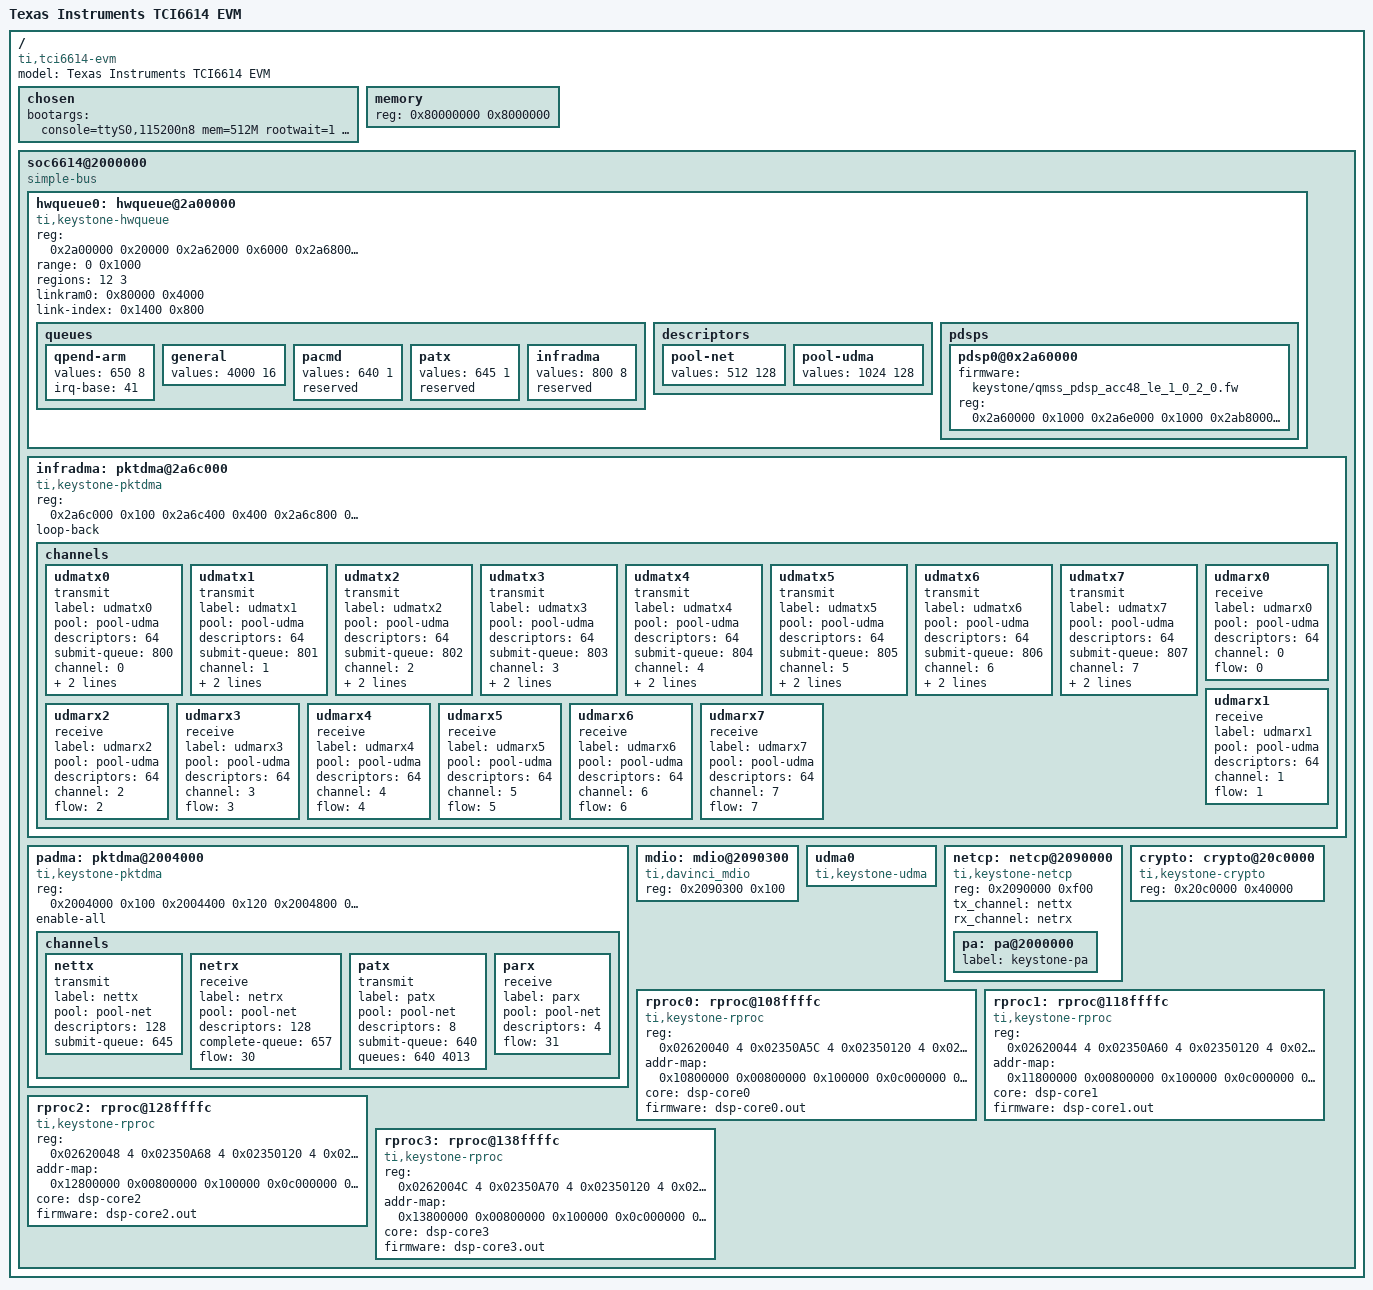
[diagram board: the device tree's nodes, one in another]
/dts-v1/;
/include/ "skeleton.dtsi"

/ {
	model = "Texas Instruments TCI6614 EVM";
	compatible = "ti,tci6614-evm";
	#address-cells = <1>;
	#size-cells = <1>;

	chosen {
		bootargs = "console=ttyS0,115200n8 mem=512M rootwait=1 rw ubi.mtd=2,2048 rootfstype=ubifs root=ubi0:rootfs";
	};

	memory {
		device_type = "memory";
		reg = <0x80000000 0x8000000>;
	};

	soc6614@2000000 {
		#address-cells = <1>;
		#size-cells = <1>;
		compatible = "simple-bus", "ti,tci6614-bus";
		ranges;

		hwqueue0: hwqueue@2a00000 {
			compatible = "ti,keystone-hwqueue";
			#address-cells = <1>;
			#size-cells = <1>;
			ranges;
			reg = <0x2a00000 0x20000	/* 0 - peek	*/
			       0x2a62000 0x6000		/* 1 - status	*/
			       0x2a68000 0x2000		/* 2 - config	*/
			       0x2a6a000 0x4000		/* 3 - region	*/
			       0x2a20000 0x20000>;	/* 4 - push/pop	*/
			range		= <0 0x1000>;
			regions		= <12 3>;
			linkram0	= <0x80000 0x4000>;
			link-index	= <0x1400 0x800>;
			queues {
				qpend-arm {
					values = <650 8>;
					irq-base= <41>;
				};
				general {
					values = <4000 16>;
				};
				pacmd {
					values = <640 1>;
					reserved;
				};
				patx {
					values = <645 1>;
					reserved;
				};
				infradma {
					values = <800 8>;
					reserved;
				};
			};
			descriptors {
				pool-net {
					values = <512 128>;	/* num_desc desc_size */
				};
				pool-udma {
					values = <1024 128>;	/* num_desc desc_size */
				};
			};
			pdsps {
				#address-cells = <1>;
				#size-cells = <1>;
				ranges;
				pdsp0@0x2a60000 {
					firmware = "keystone/qmss_pdsp_acc48_le_1_0_2_0.fw";
					reg = <0x2a60000 0x1000    /*iram */
					       0x2a6e000 0x1000    /*reg*/
					       0x2ab8000 0x4000>;  /*cmd*/
				};
			};
		};

		infradma: pktdma@2a6c000 {
			compatible = "ti,keystone-pktdma";
			reg = <0x2a6c000 0x100		/* 0 - global  */
			       0x2a6c400 0x400		/* 1 - txchan  */
			       0x2a6c800 0x400		/* 2 - rxchan  */
			       0x2a6cc00 0x400		/* 3 - txsched */
			       0x2a6d000 0x400>;	/* 4 - rxflow  */
			loop-back;
			/* big-endian; */
			/* enable-all; */
			/* debug; */
			channels {
				udmatx0 {
					transmit;
					label		= "udmatx0";
					pool		= "pool-udma";
					descriptors	= <64>;
					submit-queue	= <800>;
					/* complete-queue = <xx>; */
					/* debug; */
					channel		= <0>;
					priority	= <1>;
					flowtag		= <0>;
				};
				udmatx1 {
					transmit;
					label		= "udmatx1";
					pool		= "pool-udma";
					descriptors	= <64>;
					submit-queue	= <801>;
					/* complete-queue = <xx>; */
					/* debug; */
					channel		= <1>;
					priority	= <1>;
					flowtag		= <1>;
				};
				udmatx2 {
					transmit;
					label		= "udmatx2";
					pool		= "pool-udma";
					descriptors	= <64>;
					submit-queue	= <802>;
					/* complete-queue = <xx>; */
					/* debug; */
					channel		= <2>;
					priority	= <1>;
					flowtag		= <2>;
				};
				udmatx3 {
					transmit;
					label		= "udmatx3";
					pool		= "pool-udma";
					descriptors	= <64>;
					submit-queue	= <803>;
					/* complete-queue = <xx>; */
					/* debug; */
					channel		= <3>;
					priority	= <1>;
					flowtag		= <3>;
				};
				udmatx4 {
					transmit;
					label		= "udmatx4";
					pool		= "pool-udma";
					descriptors	= <64>;
					submit-queue	= <804>;
					/* complete-queue = <xx>; */
					/* debug; */
					channel		= <4>;
					priority	= <1>;
					flowtag		= <4>;
				};
				udmatx5 {
					transmit;
					label		= "udmatx5";
					pool		= "pool-udma";
					descriptors	= <64>;
					submit-queue	= <805>;
					/* complete-queue = <xx>; */
					/* debug; */
					channel		= <5>;
					priority	= <1>;
					flowtag		= <5>;
				};
				udmatx6 {
					transmit;
					label		= "udmatx6";
					pool		= "pool-udma";
					descriptors	= <64>;
					submit-queue	= <806>;
					/* complete-queue = <xx>; */
					/* debug; */
					channel		= <6>;
					priority	= <1>;
					flowtag		= <6>;
				};
				udmatx7 {
					transmit;
					label		= "udmatx7";
					pool		= "pool-udma";
					descriptors	= <64>;
					submit-queue	= <807>;
					/* complete-queue = <xx>; */
					/* debug; */
					channel		= <7>;
					priority	= <1>;
					flowtag		= <7>;
				};
				udmarx0 {
					receive;
					label		= "udmarx0";
					pool		= "pool-udma";
					descriptors	= <64>;
					/* submit-queue   = <xx>; */
					/* complete-queue = <xx>; */
					/* debug; */
					channel		= <0>;
					flow		= <0>;
				};
				udmarx1 {
					receive;
					label		= "udmarx1";
					pool		= "pool-udma";
					descriptors	= <64>;
					/* submit-queue   = <xx>; */
					/* complete-queue = <xx>; */
					/* debug; */
					channel		= <1>;
					flow		= <1>;
				};
				udmarx2 {
					receive;
					label		= "udmarx2";
					pool		= "pool-udma";
					descriptors	= <64>;
					/* submit-queue   = <xx>; */
					/* complete-queue = <xx>; */
					/* debug; */
					channel		= <2>;
					flow		= <2>;
				};
				udmarx3 {
					receive;
					label		= "udmarx3";
					pool		= "pool-udma";
					descriptors	= <64>;
					/* submit-queue   = <xx>; */
					/* complete-queue = <xx>; */
					/* debug; */
					channel		= <3>;
					flow		= <3>;
				};
				udmarx4 {
					receive;
					label		= "udmarx4";
					pool		= "pool-udma";
					descriptors	= <64>;
					/* submit-queue   = <xx>; */
					/* complete-queue = <xx>; */
					/* debug; */
					channel		= <4>;
					flow		= <4>;
				};
				udmarx5 {
					receive;
					label		= "udmarx5";
					pool		= "pool-udma";
					descriptors	= <64>;
					/* submit-queue   = <xx>; */
					/* complete-queue = <xx>; */
					/* debug; */
					channel		= <5>;
					flow		= <5>;
				};
				udmarx6 {
					receive;
					label		= "udmarx6";
					pool		= "pool-udma";
					descriptors	= <64>;
					/* submit-queue   = <xx>; */
					/* complete-queue = <xx>; */
					/* debug; */
					channel		= <6>;
					flow		= <6>;
				};
				udmarx7 {
					receive;
					label		= "udmarx7";
					pool		= "pool-udma";
					descriptors	= <64>;
					/* submit-queue   = <xx>; */
					/* complete-queue = <xx>; */
					/* debug; */
					channel		= <7>;
					flow		= <7>;
				};
			};
		};

		padma: pktdma@2004000 {
			compatible = "ti,keystone-pktdma";
			reg = <0x2004000 0x100		/* 0 - global  */
			       0x2004400 0x120		/* 1 - txchan  */
			       0x2004800 0x300		/* 2 - rxchan  */
			       0x2004c00 0x120		/* 3 - txsched */
			       0x2005000 0x400>;	/* 4 - rxflow  */
			/* loop-back;  */
			/* bigendian; */
			enable-all;
			/* debug; */
			channels {
				nettx {
					transmit;
					label		= "nettx";
					pool		= "pool-net";
					descriptors	= <128>;
					submit-queue	= <645>;
					/* complete-queue = <xx>; */
					/* debug; */
					/* channel = <0>; */
					/* priority = <1>; */
				};
				netrx {
					receive;
					label		= "netrx";
					pool		= "pool-net";
					descriptors	= <128>;
					/* submit-queue   = <xx>; */
					complete-queue = <657>;
					/* debug; */
					/* channel = <0>; */
					flow		= <30>;
				};
				patx {
					transmit;
					label		= "patx";
					pool		= "pool-net";
					descriptors	= <8>;
					submit-queue	= <640>;
					/* complete-queue = <xx>; */
					/* debug; */
					/* channel = <xx>; */
					/* priority = <1>; */
					queues		= <640 4013>;
				};
				parx {
					receive;
					label		= "parx";
					pool		= "pool-net";
					descriptors	= <4>;
					/* submit-queue   = <xx>; */
					/* complete-queue = <xx>; */
					/* debug; */
					/* channel = <0>; */
					flow		= <31>;
				};
			};
		};

		mdio: mdio@2090300 {
			compatible	= "ti,davinci_mdio";
			reg		= <0x2090300 0x100>;
		};

		udma0 {
			compatible = "ti,keystone-udma";
		};

		netcp: netcp@2090000 {
			reg = <0x2090000 0xf00>;
			compatible = "ti,keystone-netcp";

			tx_channel = "nettx";
			rx_channel = "netrx";
			pa: pa@2000000 {
				label = "keystone-pa";
			};

		};

		crypto: crypto@20c0000 {
			compatible = "ti,keystone-crypto";
			reg = <0x20c0000 0x40000>;
		};

		rproc0: rproc@108ffffc {
			compatible = "ti,keystone-rproc";
			reg = <0x02620040 4				/* boot address register */
			       0x02350A5C 4				/* module control register */
			       0x02350120 4				/* power domain transition command register */
			       0x02620240 4>;				/* ipc interrupt generation register */
			addr-map = <0x10800000 0x00800000 0x100000	/* l2-ram  global, local, size */
				    0x0c000000 0x0c000000 0x200000	/* msmc-sram  global, local, size */
				    0xa0000000 0xa0000000 0x20000000>;	/* ddr3-sram  global, local, size */
			core = "dsp-core0";
			firmware = "dsp-core0.out";
		};

		rproc1: rproc@118ffffc {
			compatible = "ti,keystone-rproc";
			reg = <0x02620044 4
			       0x02350A60 4
			       0x02350120 4
			       0x02620244 4>;
			addr-map = <0x11800000 0x00800000 0x100000
				    0x0c000000 0x0c000000 0x200000
				    0xa0000000 0xa0000000 0x20000000>;
			core = "dsp-core1";
			firmware = "dsp-core1.out";
		};

		rproc2: rproc@128ffffc {
			compatible = "ti,keystone-rproc";
			reg = <0x02620048 4
			       0x02350A68 4
			       0x02350120 4
			       0x02620248 4>;
			addr-map = <0x12800000 0x00800000 0x100000
				    0x0c000000 0x0c000000 0x200000
				    0xa0000000 0xa0000000 0x20000000>;
			core = "dsp-core2";
			firmware = "dsp-core2.out";
		};

		rproc3: rproc@138ffffc {
			compatible = "ti,keystone-rproc";
			reg = <0x0262004C 4
			       0x02350A70 4
			       0x02350120 4
			       0x0262024c 4>;
			addr-map = <0x13800000 0x00800000 0x100000
				    0x0c000000 0x0c000000 0x200000
				    0xa0000000 0xa0000000 0x20000000>;
			core = "dsp-core3";
			firmware = "dsp-core3.out";
		};
	};
};
